# apollo1 register map
Vendor: Ambiq Micro; Series: Apollo; File version: 1.0
CPU: CM4 r1p0, little endian, MPU, FPU, 3 interrupt priority bits
Registers are 32-bit, read-write, reset 0x0 unless marked. A register's access mark holds for its fields unless they carry their own. Offsets are from the block's base; [hi:lo] are bit positions; 'fields as' and 'values as' point back to an identical list.

## VCOMP — Voltage Comparator
Base 0x4000C000
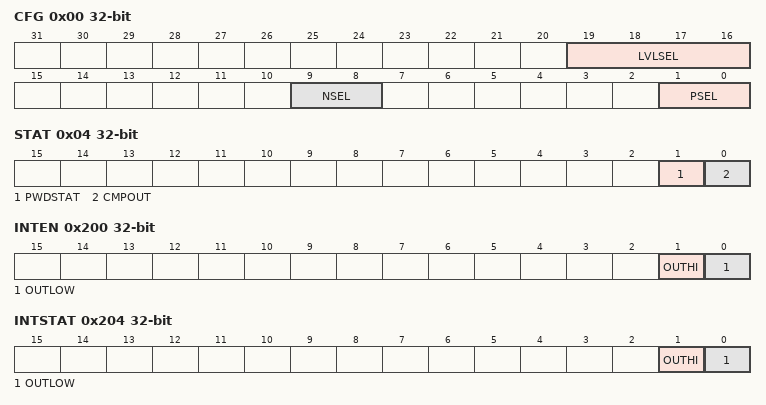
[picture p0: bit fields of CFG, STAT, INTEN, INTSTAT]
0x00 CFG — Configuration Register
  [19:16] LVLSEL — When the reference input NSEL is set to NSEL_DAC, this bitfield selects the voltage level for the negative input to the comparator.
    0=0P58V (Set Reference input to 0.58 Volts. value.); 1=0P77V (Set Reference input to 0.77 Volts. value.); 2=0P97V (Set Reference input to 0.97 Volts. value.); 3=1P16V (Set Reference input to 1.16 Volts. value.); 4=1P35V (Set Reference input to 1.35 Volts. value.); 5=1P55V (Set Reference input to 1.55 Volts. value.); 6=1P74V (Set Reference input to 1.74 Volts. value.); 7=1P93V (Set Reference input to 1.93 Volts. value.); 8=2P13V (Set Reference input to 2.13 Volts. value.); 9=2P32V (Set Reference input to 2.32 Volts. value.); 10=2P51V (Set Reference input to 2.51 Volts. value.); 11=2P71V (Set Reference input to 2.71 Volts. value.); 12=2P90V (Set Reference input to 2.90 Volts. value.); 13=3P09V (Set Reference input to 3.09 Volts. value.); 14=3P29V (Set Reference input to 3.29 Volts. value.); 15=3P48V (Set Reference input to 3.48 Volts. value.)
  [9:8] NSEL — This bitfield selects the negative input to the comparator.
    0=VREFEXT1 (Use external reference 1 for reference input. value.); 1=VREFEXT2 (Use external reference 2 for reference input. value.); 3=VREFEXT3 (Use external reference 3 for reference input. value.)
  [1:0] PSEL — This bitfield selects the positive input to the comparator.
    0=VDDADJ (Use VDDADJ for the positive input. value.); 1=VTEMP (Use the temperature sensor output for the positive input. value.); 2=VEXT1 (Use external voltage 1 for positive input. value.); 3=VEXT2 (Use external voltage 1 for positive input. value.)
0x04 STAT — Status Register
  [1] PWDSTAT — This bit indicates the power down state of the voltage comparator.
    1=POWERED_DOWN (The voltage comparator is powered down. value.)
  [0] CMPOUT — This bit is 1 if the positive input of the comparator is greater than the negative input.
    0=VOUT_LOW (The negative input of the comparator is greater than the positive input. value.); 1=VOUT_HIGH (The positive input of the comparator is greater than the negative input. value.)
0x08 PWDKEY — Key Register for Powering Down the Voltage Comparator
  [31:0] PWDKEY — Key register value.
    55=Key (Key value.)
0x200 INTEN — Voltage Comparator Interrupt registers: Enable
  [1] OUTHI — This bit is the vcompout high interrupt.
  [0] OUTLOW — This bit is the vcompout low interrupt.
0x204 INTSTAT — Voltage Comparator Interrupt registers: Status
  fields as INTEN
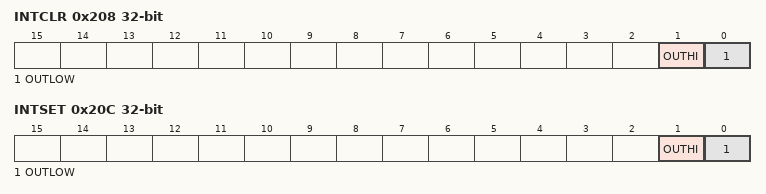
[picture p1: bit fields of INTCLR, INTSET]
0x208 INTCLR — Voltage Comparator Interrupt registers: Clear
  fields as INTEN
0x20C INTSET — Voltage Comparator Interrupt registers: Set
  fields as INTEN

## WDT — Watchdog Timer
Base 0x40024000
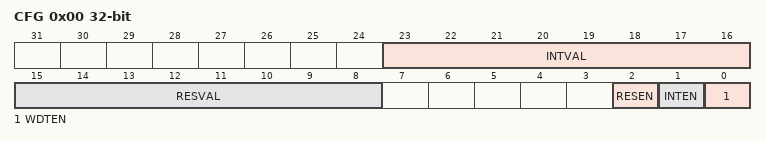
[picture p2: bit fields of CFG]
0x00 CFG — Configuration Register
  [23:16] INTVAL — This bitfield is the compare value for counter bits 7:0 to generate a watchdog interrupt.
  [15:8] RESVAL — This bitfield is the compare value for counter bits 7:0 to generate a watchdog reset.
  [2] RESEN — This bitfield enables the WDT reset.
  [1] INTEN — This bitfield enables the WDT interrupt. Note : This bit must be set before the interrupt status bit will reflect a watchdog timer expiration. The IER interrupt register must also be enabled for a WDT interrupt to be sent to the NVIC.
  [0] WDTEN — This bitfield enables the WDT.
0x04 RSTRT — Restart the watchdog timer
  [7:0] RSTRT — Writing 0xB2 to WDTRSTRT restarts the watchdog timer.
    178=KEYVALUE (This is the key value to write to WDTRSTRT to restart the WDT. value.)
0x08 LOCK — Locks the WDT
  [7:0] LOCK — Writing 0x3A locks the watchdog timer. Once locked, the WDTCFG reg cannot be written and WDTEN is set.
    58=KEYVALUE (This is the key value to write to WDTLOCK to lock the WDT. value.)
0x200 INTEN — WDT Interrupt register: Enable
  [0] WDTINT — Watchdog Timer Interrupt.
0x204 INTSTAT — WDT Interrupt register: Status
  [0] WDTINT — Watchdog Timer Interrupt.
0x208 INTCLR — WDT Interrupt register: Clear
  [0] WDTINT — Watchdog Timer Interrupt.
0x20C INTSET — WDT Interrupt register: Set
  [0] WDTINT — Watchdog Timer Interrupt.
